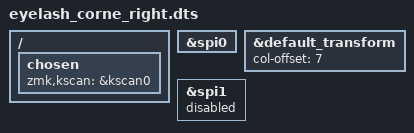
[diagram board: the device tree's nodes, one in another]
/dts-v1/;

/* SoC */
#include <nordic/nrf52840_qiaa.dtsi>

/* Shared keyboard defs */
#include "eyelash_corne.dtsi"

/* Nice!View SPI bus */
nice_view_spi: &spi0 {
    status = "okay";
};

 / {
    chosen {
        zmk,kscan = &kscan0;
    };
 };

&default_transform {
    col-offset = <7>;
};

&spi1 {
    status = "disabled";
};
